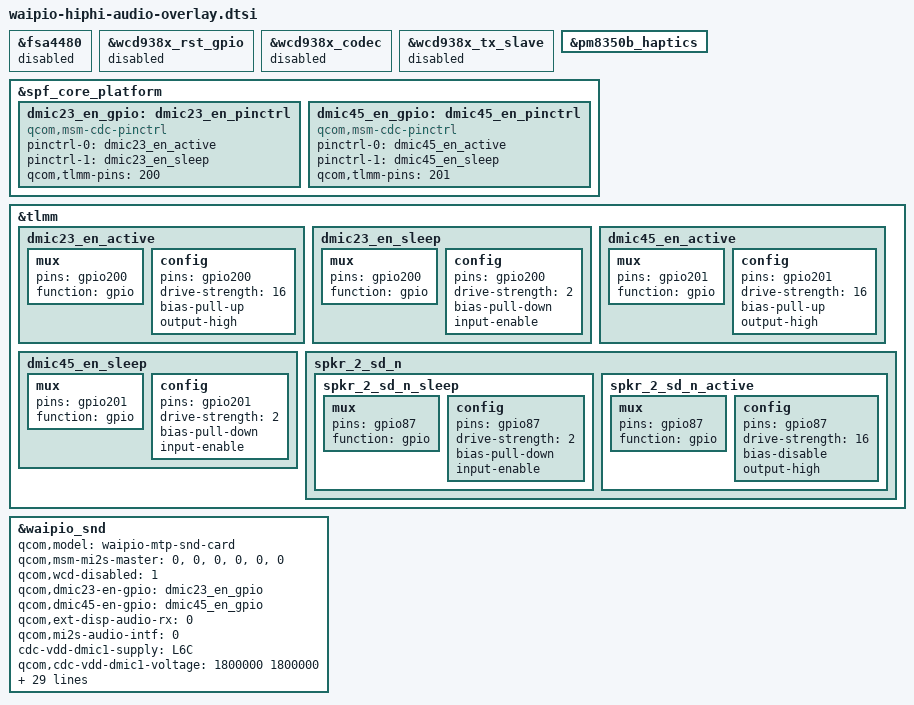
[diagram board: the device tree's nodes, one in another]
&fsa4480 {
	status = "disabled";
};

&wcd938x_rst_gpio {
	status = "disabled";
};

&wcd938x_codec {
        status = "disabled";
};

&wcd938x_tx_slave {
	status = "disabled";
};

&pm8350b_haptics {
	status = "ok";
};

&spf_core_platform {
	dmic23_en_gpio: dmic23_en_pinctrl {
		compatible = "qcom,msm-cdc-pinctrl";
		pinctrl-names = "aud_active", "aud_sleep";
		pinctrl-0 = <&dmic23_en_active>;
		pinctrl-1 = <&dmic23_en_sleep>;
		qcom,tlmm-pins = <200>;
		#gpio-cells = <0>;
	};
	dmic45_en_gpio: dmic45_en_pinctrl {
		compatible = "qcom,msm-cdc-pinctrl";
		pinctrl-names = "aud_active", "aud_sleep";
		pinctrl-0 = <&dmic45_en_active>;
		pinctrl-1 = <&dmic45_en_sleep>;
		qcom,tlmm-pins = <201>;
		#gpio-cells = <0>;
	};
};

&tlmm {
	dmic23_en_active: dmic23_en_active {
		mux {
			pins = "gpio200";
			function = "gpio";
		};

		config {
			pins = "gpio200";
			drive-strength = <16>;
			bias-pull-up;
			output-high;
		};
	};
	dmic23_en_sleep: dmic23_en_sleep {
		mux {
			pins = "gpio200";
			function = "gpio";
		};

		config {
			pins = "gpio200";
			drive-strength = <2>;   /* 2 mA */
			bias-pull-down;
			input-enable;
		};
	};
	dmic45_en_active: dmic45_en_active {
		mux {
			pins = "gpio201";
			function = "gpio";
		};

		config {
			pins = "gpio201";
			drive-strength = <16>;
			bias-pull-up;
			output-high;
		};
	};
	dmic45_en_sleep: dmic45_en_sleep {
		mux {
			pins = "gpio201";
			function = "gpio";
		};

		config {
			pins = "gpio201";
			drive-strength = <2>;   /* 2 mA */
			bias-pull-down;
			input-enable;
		};
	};

	spkr_2_sd_n {
		spkr_2_sd_n_sleep: spkr_2_sd_n_sleep {
			mux {
				pins = "gpio87";
				function = "gpio";
			};

			config {
				pins = "gpio87";
				drive-strength = <2>;   /* 2 mA */
				bias-pull-down;
				input-enable;
			};
		};

		spkr_2_sd_n_active: spkr_2_sd_n_active {
			mux {
				pins = "gpio87";
				function = "gpio";
			};

			config {
				pins = "gpio87";
				drive-strength = <16>;   /* 16 mA */
				bias-disable;
				output-high;
			};
		};
	};
};

&waipio_snd {
	qcom,model = "waipio-mtp-snd-card";
	qcom,msm-mi2s-master = <0>, <0>, <0>, <0>, <0>, <0>;
	qcom,wcd-disabled = <1>;
	qcom,dmic23-en-gpio = <&dmic23_en_gpio>;
	qcom,dmic45-en-gpio = <&dmic45_en_gpio>;
	qcom,ext-disp-audio-rx = <0>;
	qcom,mi2s-audio-intf = <0>;

	cdc-vdd-dmic1-supply = <&L6C>;
	qcom,cdc-vdd-dmic1-voltage = <1800000 1800000>;
	qcom,cdc-vdd-dmic1-current = <30000>;

	cdc-vdd-dmic2-supply = <&S1C>;
	qcom,cdc-vdd-dmic2-voltage = <1800000 1800000>;
	qcom,cdc-vdd-dmic2-current = <30000>;

	cdc-vdd-dmic3-supply = <&S1C>;
	qcom,cdc-vdd-dmic3-voltage = <1800000 1800000>;
	qcom,cdc-vdd-dmic3-current = <30000>;

	qcom,cdc-static-supplies = "cdc-vdd-dmic1",
			"cdc-vdd-dmic2", "cdc-vdd-dmic3";
	qcom,audio-routing =
		"TX DMIC0", "Digital Mic0",
		"TX DMIC1", "Digital Mic1",
		"TX DMIC2", "Digital Mic2",
		"TX DMIC3", "Digital Mic3",
		"WSA SRC0_INP", "SRC0",
		"HAP_IN", "PCM_OUT",
		"WSA_TX DEC0_INP", "TX DEC0 MUX",
		"WSA_TX DEC1_INP", "TX DEC1 MUX",
		"RX_TX DEC0_INP", "TX DEC0 MUX",
		"RX_TX DEC1_INP", "TX DEC1 MUX",
		"RX_TX DEC2_INP", "TX DEC2 MUX",
		"RX_TX DEC3_INP", "TX DEC3 MUX",
		"SpkrLeft IN", "WSA_SPK1 OUT",
		"SpkrRight IN", "WSA_SPK2 OUT",
		"VA SWR_INPUT", "VA_SWR_CLK",
		"VA_AIF1 CAP", "VA_SWR_CLK",
		"VA_AIF2 CAP", "VA_SWR_CLK",
		"VA_AIF3 CAP", "VA_SWR_CLK",
		"VA DMIC0", "Digital Mic0",
		"VA DMIC1", "Digital Mic1",
		"VA DMIC2", "Digital Mic2",
		"VA DMIC3", "Digital Mic3";
	asoc-codec  = <&stub_codec>, <&lpass_cdc>,
				<&swr_haptics>,
				<&wsa883x_0221>, <&wsa883x_0222>;
	asoc-codec-names = "msm-stub-codec.1", "lpass-cdc",
				"swr-haptics",
				"wsa-codec1", "wsa-codec2";
};
